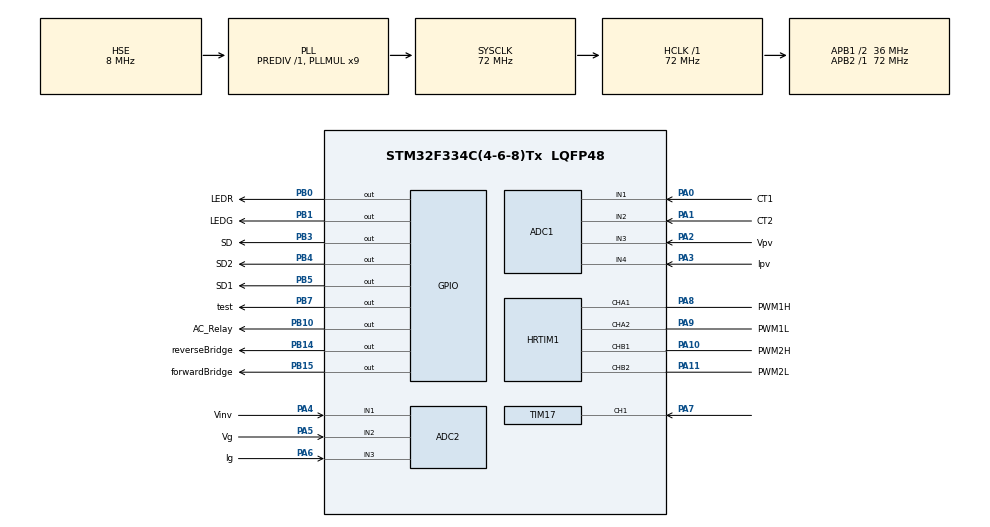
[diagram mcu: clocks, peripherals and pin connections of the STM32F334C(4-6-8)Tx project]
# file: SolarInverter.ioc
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ADC1.Channel-0\#ChannelRegularConversion=ADC_CHANNEL_1
ADC1.Channel-1\#ChannelRegularConversion=ADC_CHANNEL_2
ADC1.Channel-2\#ChannelRegularConversion=ADC_CHANNEL_3
ADC1.Channel-4\#ChannelRegularConversion=ADC_CHANNEL_4
ADC1.ClockPrescaler=ADC_CLOCK_ASYNC_DIV1
ADC1.ContinuousConvMode=DISABLE
ADC1.DMAContinuousRequests=ENABLE
ADC1.EOCSelection=ADC_EOC_SINGLE_CONV
ADC1.EnableInjectedConversion=DISABLE
ADC1.ExternalTrigConv=ADC_EXTERNALTRIGCONV_T1_TRGO
ADC1.Mode=ADC_DUALMODE_REGSIMULT
ADC1.NbrOfConversion=4
ADC1.NbrOfConversionFlag=1
ADC1.Offset-0\#ChannelRegularConversion=0
ADC1.Offset-1\#ChannelRegularConversion=0
ADC1.Offset-2\#ChannelRegularConversion=0
ADC1.Offset-4\#ChannelRegularConversion=0
ADC1.OffsetNumber-0\#ChannelRegularConversion=ADC_OFFSET_NONE
ADC1.OffsetNumber-1\#ChannelRegularConversion=ADC_OFFSET_NONE
ADC1.OffsetNumber-2\#ChannelRegularConversion=ADC_OFFSET_NONE
ADC1.OffsetNumber-4\#ChannelRegularConversion=ADC_OFFSET_NONE
ADC1.Rank-0\#ChannelRegularConversion=1
ADC1.Rank-1\#ChannelRegularConversion=2
ADC1.Rank-2\#ChannelRegularConversion=3
ADC1.Rank-4\#ChannelRegularConversion=4
ADC1.SamplingTime-0\#ChannelRegularConversion=ADC_SAMPLETIME_1CYCLE_5
ADC1.SamplingTime-1\#ChannelRegularConversion=ADC_SAMPLETIME_1CYCLE_5
ADC1.SamplingTime-2\#ChannelRegularConversion=ADC_SAMPLETIME_1CYCLE_5
ADC1.SamplingTime-4\#ChannelRegularConversion=ADC_SAMPLETIME_1CYCLE_5
ADC1.SequencerNbRanks=1
ADC1.SubFamily=STM32F334x8
ADC1.master=1
ADC2.Channel-4\#ChannelRegularConversion=ADC_CHANNEL_1
ADC2.Channel-5\#ChannelRegularConversion=ADC_CHANNEL_2
ADC2.Channel-6\#ChannelRegularConversion=ADC_CHANNEL_3
ADC2.Channel-7\#ChannelRegularConversion=ADC_CHANNEL_VREFINT
ADC2.ContinuousConvMode=DISABLE
ADC2.DMAContinuousRequests=DISABLE
ADC2.EOCSelection=ADC_EOC_SEQ_CONV
ADC2.EnableInjectedConversion=DISABLE
ADC2.EnableRegularConversion=ENABLE
ADC2.Mode=ADC_DUALMODE_REGSIMULT
ADC2.NbrOfConversion=4
ADC2.NbrOfConversionFlag=1
ADC2.Offset-4\#ChannelRegularConversion=0
ADC2.Offset-5\#ChannelRegularConversion=0
ADC2.Offset-6\#ChannelRegularConversion=0
ADC2.Offset-7\#ChannelRegularConversion=0
ADC2.OffsetNumber-4\#ChannelRegularConversion=ADC_OFFSET_NONE
ADC2.OffsetNumber-5\#ChannelRegularConversion=ADC_OFFSET_NONE
ADC2.OffsetNumber-6\#ChannelRegularConversion=ADC_OFFSET_NONE
ADC2.OffsetNumber-7\#ChannelRegularConversion=ADC_OFFSET_NONE
ADC2.Rank-4\#ChannelRegularConversion=1
ADC2.Rank-5\#ChannelRegularConversion=2
ADC2.Rank-6\#ChannelRegularConversion=3
ADC2.Rank-7\#ChannelRegularConversion=4
ADC2.SamplingTime-4\#ChannelRegularConversion=ADC_SAMPLETIME_1CYCLE_5
ADC2.SamplingTime-5\#ChannelRegularConversion=ADC_SAMPLETIME_1CYCLE_5
ADC2.SamplingTime-6\#ChannelRegularConversion=ADC_SAMPLETIME_1CYCLE_5
ADC2.SamplingTime-7\#ChannelRegularConversion=ADC_SAMPLETIME_1CYCLE_5
ADC2.SamplingTimeOPAMP-7\#ChannelRegularConversion=ADC_SAMPLETIME_61CYCLES_5
ADC2.SubFamily=STM32F334x8
Dma.ADC1.0.Direction=DMA_PERIPH_TO_MEMORY
Dma.ADC1.0.Instance=DMA1_Channel1
Dma.ADC1.0.MemDataAlignment=DMA_MDATAALIGN_WORD
Dma.ADC1.0.MemInc=DMA_MINC_ENABLE
Dma.ADC1.0.Mode=DMA_CIRCULAR
Dma.ADC1.0.PeriphDataAlignment=DMA_PDATAALIGN_WORD
Dma.ADC1.0.PeriphInc=DMA_PINC_DISABLE
Dma.ADC1.0.Priority=DMA_PRIORITY_MEDIUM
Dma.Request0=ADC1
HRTIM1.ADCTrigger_Id1=__NULL
HRTIM1.CompareUnit1-MasterTimer=HRTIM_COMPAREUNIT_1
HRTIM1.CompareUnit1-Output_TA1TA2=HRTIM_COMPAREUNIT_1
HRTIM1.CompareUnit1-Output_TB1TB2=HRTIM_COMPAREUNIT_1
HRTIM1.CompareUnit2-Output_TA1TA2=HRTIM_COMPAREUNIT_2
HRTIM1.CompareUnit2-Output_TB1TB2=HRTIM_COMPAREUNIT_2
HRTIM1.CompareUnit3-Output_TA1TA2=HRTIM_COMPAREUNIT_3
HRTIM1.CompareUnit3-Output_TB1TB2=HRTIM_COMPAREUNIT_3
HRTIM1.CompareValue1-MasterTimer=23040
HRTIM1.CompareValue1-Output_TA1TA2=100
HRTIM1.CompareValue1-Output_TB1TB2=100
HRTIM1.CompareValue2-Output_TA1TA2=100
HRTIM1.CompareValue2-Output_TB1TB2=100
HRTIM1.CompareValue3-Output_TA1TA2=100
HRTIM1.CompareValue3-Output_TB1TB2=100
HRTIM1.DeadTimeInsertion-Output_TA1TA2=HRTIM_TIMDEADTIMEINSERTION_DISABLED
HRTIM1.NumberResetSource1-Output_TA1TA2=1
HRTIM1.NumberResetSource1-Output_TB1TB2=1
HRTIM1.NumberResetSource2_TA=1
HRTIM1.NumberResetSource2_TB=1
HRTIM1.NumberResetTrigger-Output_TA1TA2=1
HRTIM1.NumberResetTrigger-Output_TB1TB2=1
HRTIM1.NumberSetSource1-Output_TA1TA2=1
HRTIM1.NumberSetSource1-Output_TB1TB2=1
HRTIM1.NumberSetSource2_TA=1
HRTIM1.NumberSetSource2_TB=1
HRTIM1.NumberUpdateTrigger-Output_TA1TA2=0
HRTIM1.Periode_MASTER=46080
HRTIM1.Periode_TA=46080
HRTIM1.Periode_TB=46080
HRTIM1.PreloadEnable-Output_TA1TA2=HRTIM_PRELOAD_ENABLED
HRTIM1.PreloadEnable-Output_TB1TB2=HRTIM_PRELOAD_ENABLED
HRTIM1.PrescalerRatio_MASTER=HRTIM_PRESCALERRATIO_MUL32
HRTIM1.RepetitionUpdate-Output_TA1TA2=HRTIM_UPDATEONREPETITION_ENABLED
HRTIM1.RepetitionUpdate-Output_TB1TB2=HRTIM_UPDATEONREPETITION_ENABLED
HRTIM1.ResetOutput1_Source1-Output_TA1TA2=HRTIM_OUTPUTRESET_TIMCMP3
HRTIM1.ResetOutput1_Source1-Output_TB1TB2=HRTIM_OUTPUTRESET_TIMCMP3
HRTIM1.ResetOutput2_Source1-Output_TA1TA2=HRTIM_OUTPUTRESET_TIMCMP1
HRTIM1.ResetOutput2_Source1-Output_TB1TB2=HRTIM_OUTPUTRESET_TIMCMP1
HRTIM1.ResetTrigger1-Output_TA1TA2=HRTIM_TIMRESETTRIGGER_MASTER_PER
HRTIM1.ResetTrigger1-Output_TB1TB2=HRTIM_TIMRESETTRIGGER_MASTER_CMP1
HRTIM1.SetOutput1_Source1-Output_TA1TA2=HRTIM_OUTPUTSET_TIMCMP2
HRTIM1.SetOutput1_Source1-Output_TB1TB2=HRTIM_OUTPUTSET_TIMCMP2
HRTIM1.SetOutput2_Source1-Output_TA1TA2=HRTIM_OUTPUTSET_MASTERPER
HRTIM1.SetOutput2_Source1-Output_TB1TB2=HRTIM_OUTPUTSET_MASTERCMP1
Mcu.Family=STM32F3
Mcu.Name=STM32F334C(4-6-8)Tx
Mcu.Package=LQFP48
NVIC.DMA1_Channel1_IRQn=true\:0\:0\:true\:false\:true\:false\:true\:true
NVIC.PriorityGroup=NVIC_PRIORITYGROUP_4
NVIC.TIM1_TRG_COM_TIM17_IRQn=true\:1\:0\:true\:false\:true\:true\:true\:true
PA0.GPIO_Label=CT1
PA0.Mode=IN1-Single-Ended
PA0.Signal=ADC1_IN1
PA1.GPIO_Label=CT2
PA1.Mode=IN2-Single-Ended
PA1.Signal=ADC1_IN2
PA10.GPIO_Label=PWM2H
PA10.Mode=Output_TB1TB2
PA10.Signal=HRTIM1_CHB1
PA11.GPIO_Label=PWM2L
PA11.Mode=Output_TB1TB2
PA11.Signal=HRTIM1_CHB2
PA13.Mode=Serial_Wire
PA13.Signal=SYS_JTMS-SWDIO
PA14.Mode=Serial_Wire
PA14.Signal=SYS_JTCK-SWCLK
PA2.GPIO_Label=Vpv
PA2.Mode=IN3-Single-Ended
PA2.Signal=ADC1_IN3
PA3.GPIO_Label=Ipv
PA3.Mode=IN4-Single-Ended
PA3.Signal=ADC1_IN4
PA4.GPIO_Label=Vinv
PA4.Mode=IN1-Single-Ended
PA4.Signal=ADC2_IN1
PA5.GPIO_Label=Vg
PA5.Mode=IN2-Single-Ended
PA5.Signal=ADC2_IN2
PA6.GPIO_Label=Ig
PA6.Mode=IN3-Single-Ended
PA6.Signal=ADC2_IN3
PA7.Signal=S_TIM17_CH1
PA8.GPIO_Label=PWM1H
PA8.Mode=Output_TA1TA2
PA8.Signal=HRTIM1_CHA1
PA9.GPIO_Label=PWM1L
PA9.Mode=Output_TA1TA2
PA9.Signal=HRTIM1_CHA2
PB0.GPIO_Label=LEDR
PB0.GPIO_PuPd=GPIO_PULLUP
PB0.PinState=GPIO_PIN_SET
PB0.Signal=GPIO_Output
PB1.GPIO_Label=LEDG
PB1.GPIO_PuPd=GPIO_PULLUP
PB1.PinState=GPIO_PIN_SET
PB1.Signal=GPIO_Output
PB10.GPIO_Label=AC_Relay
PB10.GPIO_PuPd=GPIO_PULLDOWN
PB10.Signal=GPIO_Output
PB14.GPIO_Label=reverseBridge
PB14.GPIO_PuPd=GPIO_NOPULL
PB14.GPIO_Speed=GPIO_SPEED_FREQ_HIGH
PB14.Signal=GPIO_Output
PB15.GPIO_Label=forwardBridge
PB15.GPIO_PuPd=GPIO_NOPULL
PB15.GPIO_Speed=GPIO_SPEED_FREQ_HIGH
PB15.PinState=GPIO_PIN_RESET
PB15.Signal=GPIO_Output
PB3.GPIO_Label=SD
PB3.GPIO_PuPd=GPIO_PULLDOWN
PB3.Signal=GPIO_Output
PB4.GPIO_Label=SD2
PB4.GPIO_PuPd=GPIO_PULLDOWN
PB4.Signal=GPIO_Output
PB5.GPIO_Label=SD1
PB5.GPIO_PuPd=GPIO_PULLDOWN
PB5.Signal=GPIO_Output
PB7.GPIO_FM7=SYSCFG_CFGR1_I2C_PB7_FMP
PB7.GPIO_Label=test
PB7.Signal=GPIO_Output
PF0\ /\ OSC_IN.Mode=HSE-External-Oscillator
PF0\ /\ OSC_IN.Signal=RCC_OSC_IN
PF1\ /\ OSC_OUT.Mode=HSE-External-Oscillator
PF1\ /\ OSC_OUT.Signal=RCC_OSC_OUT
ProjectManager.HeapSize=0x200
ProjectManager.StackSize=0x400
ProjectManager.TargetToolchain=STM32CubeIDE
RCC.AHBFreq_Value=72000000
RCC.APB1CLKDivider=RCC_HCLK_DIV2
RCC.APB1Freq_Value=36000000
RCC.APB1TimFreq_Value=72000000
RCC.APB2Freq_Value=72000000
RCC.APB2TimFreq_Value=72000000
RCC.CortexFreq_Value=72000000
RCC.HCLKFreq_Value=72000000
RCC.HRTIMSelection=RCC_HRTIM1CLK_PLLCLK
RCC.HSE_VALUE=8000000
RCC.HSI_VALUE=8000000
RCC.LSE_VALUE=32768
RCC.PLLMUL=RCC_PLL_MUL9
RCC.PLLSourceVirtual=RCC_PLLSOURCE_HSE
RCC.SYSCLKFreq_VALUE=72000000
RCC.SYSCLKSourceVirtual=RCC_SYSCLKSOURCE_PLLCLK
SH.S_TIM17_CH1.0=TIM17_CH1,Input_Capture1_from_TI1
STMicroelectronics.X-CUBE-ALGOBUILD.1.3.0.LibraryCcDSPOoLibraryJjDSPOoLibrary=true
TIM1.AutoReloadPreload=TIM_AUTORELOAD_PRELOAD_ENABLE
TIM1.Period=100-1
TIM1.Prescaler=72-1
TIM1.TIM_MasterOutputTrigger=TIM_TRGO_UPDATE
TIM17.AutoReloadPreload=TIM_AUTORELOAD_PRELOAD_ENABLE
TIM17.Channel=TIM_CHANNEL_1
TIM2.AutoReloadPreload=TIM_AUTORELOAD_PRELOAD_ENABLE
TIM2.Period=1000-1
TIM2.Prescaler=72-1
TIM2.TIM_MasterOutputTrigger=TIM_TRGO_UPDATE
VP_ADC2_Vref_Input.Mode=IN-Vrefint
VP_HRTIM1_VS_hrtimMasterTimerNoOutput.Mode=MasterTimer
VP_STMicroelectronics.X-CUBE-ALGOBUILD_VS_DSPOoLibraryJjLibrary_1.3.0_1.3.0.Mode=DSPOoLibraryJjLibrary
VP_TIM17_VS_ClockSourceINT.Mode=Enable_Timer
VP_TIM1_VS_ClockSourceINT.Mode=Internal
VP_TIM2_VS_ClockSourceINT.Mode=Internal
board=custom

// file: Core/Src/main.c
/* USER CODE BEGIN Header */
/**
  ******************************************************************************
  * @file           : main.c
  * @brief          : Main program body
  ******************************************************************************
  * @attention
  *
  * Copyright (c) 2024 STMicroelectronics.
  * All rights reserved.
  *
  * This software is licensed under terms that can be found in the LICENSE file
  * in the root directory of this software component.
  * If no LICENSE file comes with this software, it is provided AS-IS.
  *
  ******************************************************************************
  */
/* USER CODE END Header */
#include "main.h"
#include "adc.h"
#include "dma.h"
#include "hrtim.h"
#include "tim.h"
#include "gpio.h"

/* USER CODE BEGIN Includes */

#include <common.h>
#include <stateMachine.h>

/* USER CODE END Includes */

void SystemClock_Config(void);

int main(void)
{

  /* USER CODE BEGIN 1 */
	//调试锁相�???????
#if 0
	sogiPll_init(&gridPll);
	sogiConfig(&gridPll,
	                     50,
	                     10000,
	                     (float32_t) 166.9743385,
	                     (float32_t) -166.2661165);
	sogiPllOsgCofficientCalc(&gridPll);
#endif
  /* USER CODE END 1 */

  /* MCU Configuration--------------------------------------------------------*/

  /* Reset of all peripherals, Initializes the Flash interface and the Systick. */
  HAL_Init();

  /* Configure the system clock */
  SystemClock_Config();

  /* Initialize all configured peripherals */
  MX_GPIO_Init();
  MX_DMA_Init();
  MX_ADC1_Init();
  MX_ADC2_Init();
  MX_HRTIM1_Init();
  MX_TIM17_Init();
  MX_TIM1_Init();
  MX_TIM2_Init();
  /* USER CODE BEGIN 2 */
  fsmInit(&stFsm, 0);
  runInit();
  /* USER CODE END 2 */

  /* Infinite loop */
  while(1)
  {

    /* USER CODE BEGIN 3 */
	  startFsm();

  }
  /* USER CODE END 3 */
}

void SystemClock_Config(void)
{
  RCC_OscInitTypeDef RCC_OscInitStruct = {0};
  RCC_ClkInitTypeDef RCC_ClkInitStruct = {0};
  RCC_PeriphCLKInitTypeDef PeriphClkInit = {0};

  /** Initializes the RCC Oscillators according to the specified parameters
  * in the RCC_OscInitTypeDef structure.
  */
  RCC_OscInitStruct.OscillatorType = RCC_OSCILLATORTYPE_HSE;
  RCC_OscInitStruct.HSEState = RCC_HSE_ON;
  RCC_OscInitStruct.HSEPredivValue = RCC_HSE_PREDIV_DIV1;
  RCC_OscInitStruct.HSIState = RCC_HSI_ON;
  RCC_OscInitStruct.PLL.PLLState = RCC_PLL_ON;
  RCC_OscInitStruct.PLL.PLLSource = RCC_PLLSOURCE_HSE;
  RCC_OscInitStruct.PLL.PLLMUL = RCC_PLL_MUL9;
  if (HAL_RCC_OscConfig(&RCC_OscInitStruct) != HAL_OK)
  {
    Error_Handler();
  }

  /** Initializes the CPU, AHB and APB buses clocks
  */
  RCC_ClkInitStruct.ClockType = RCC_CLOCKTYPE_HCLK|RCC_CLOCKTYPE_SYSCLK
                              |RCC_CLOCKTYPE_PCLK1|RCC_CLOCKTYPE_PCLK2;
  RCC_ClkInitStruct.SYSCLKSource = RCC_SYSCLKSOURCE_PLLCLK;
  RCC_ClkInitStruct.AHBCLKDivider = RCC_SYSCLK_DIV1;
  RCC_ClkInitStruct.APB1CLKDivider = RCC_HCLK_DIV2;
  RCC_ClkInitStruct.APB2CLKDivider = RCC_HCLK_DIV1;

  if (HAL_RCC_ClockConfig(&RCC_ClkInitStruct, FLASH_LATENCY_2) != HAL_OK)
  {
    Error_Handler();
  }
  PeriphClkInit.PeriphClockSelection = RCC_PERIPHCLK_HRTIM1|RCC_PERIPHCLK_TIM1
                              |RCC_PERIPHCLK_ADC12;
  PeriphClkInit.Adc12ClockSelection = RCC_ADC12PLLCLK_DIV1;
  PeriphClkInit.Tim1ClockSelection = RCC_TIM1CLK_HCLK;
  PeriphClkInit.Hrtim1ClockSelection = RCC_HRTIM1CLK_PLLCLK;
  if (HAL_RCCEx_PeriphCLKConfig(&PeriphClkInit) != HAL_OK)
  {
    Error_Handler();
  }
}

void Error_Handler(void)
{
  __disable_irq();
  while (1)
  {
  }
}
